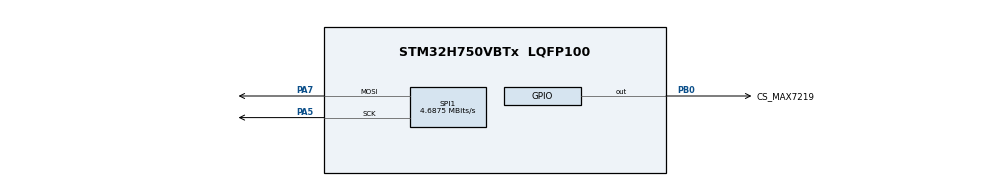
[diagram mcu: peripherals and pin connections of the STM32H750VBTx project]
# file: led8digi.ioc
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Mcu.Family=STM32H7
Mcu.Name=STM32H750VBTx
Mcu.Package=LQFP100
NVIC.PriorityGroup=NVIC_PRIORITYGROUP_4
PA5.Mode=TX_Only_Simplex_Unidirect_Master
PA5.Signal=SPI1_SCK
PA7.Mode=TX_Only_Simplex_Unidirect_Master
PA7.Signal=SPI1_MOSI
PB0.GPIO_Label=CS_MAX7219
PB0.GPIO_PuPd=GPIO_NOPULL
PB0.GPIO_Speed=GPIO_SPEED_FREQ_VERY_HIGH
PB0.Signal=GPIO_Output
PH0-OSC_IN\ (PH0).Mode=HSE-External-Oscillator
PH0-OSC_IN\ (PH0).Signal=RCC_OSC_IN
PH1-OSC_OUT\ (PH1).Mode=HSE-External-Oscillator
PH1-OSC_OUT\ (PH1).Signal=RCC_OSC_OUT
ProjectManager.HeapSize=0x200
ProjectManager.StackSize=0x400
ProjectManager.TargetToolchain=STM32CubeIDE
RCC.ADCFreq_Value=129000000
RCC.APB1Freq_Value=64000000
RCC.APB2Freq_Value=64000000
RCC.APB3Freq_Value=64000000
RCC.APB4Freq_Value=64000000
RCC.CortexFreq_Value=64000000
RCC.DIVM1=4
RCC.DIVN1=9
RCC.HCLKFreq_Value=64000000
RCC.PLL1_VCI_Range=RCC_PLL1VCIRANGE_3
RCC.PLLFRACN=3072
RCC.PREFETCH_ENABLE=1
RCC.SYSCLKFreq_VALUE=64000000
RCC.USBFreq_Value=75000000
SPI1.BaudRatePrescaler=SPI_BAUDRATEPRESCALER_16
SPI1.CalculateBaudRate=4.6875 MBits/s
SPI1.DataSize=SPI_DATASIZE_8BIT
SPI1.Direction=SPI_DIRECTION_2LINES_TXONLY
SPI1.Mode=SPI_MODE_MASTER
SPI1.VirtualType=VM_MASTER
board=custom

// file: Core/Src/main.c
/* USER CODE BEGIN Header */
/**
  ******************************************************************************
  * @file           : main.c
  * @brief          : Main program body
  ******************************************************************************
  * @attention
  *
  * Copyright (c) 2023 STMicroelectronics.
  * All rights reserved.
  *
  * This software is licensed under terms that can be found in the LICENSE file
  * in the root directory of this software component.
  * If no LICENSE file comes with this software, it is provided AS-IS.
  *
  ******************************************************************************
  */
/* USER CODE END Header */
#include "main.h"

/* USER CODE BEGIN Includes */
#include "max7219.h"
/* USER CODE END Includes */

SPI_HandleTypeDef hspi1;

void SystemClock_Config(void);
static void MX_GPIO_Init(void);
static void MX_SPI1_Init(void);

int main(void)
{

  /* MCU Configuration--------------------------------------------------------*/

  /* Reset of all peripherals, Initializes the Flash interface and the Systick. */
  HAL_Init();

  /* Configure the system clock */
  SystemClock_Config();

  /* Initialize all configured peripherals */
  MX_GPIO_Init();
  MX_SPI1_Init();
  /* USER CODE BEGIN 2 */
  max7219_Init(7);
  max7219_Decode_On();

  /* USER CODE END 2 */

  /* Infinite loop */
  while (1)
  {

    /* USER CODE BEGIN 3 */
	  max7219_Clean();
	    max7219_PrintFtos(DIGIT_8, -3.14, 2);
	    max7219_PrintDigit(DIGIT_4, LETTER_H, false);
	    max7219_PrintDigit(DIGIT_3, LETTER_E, false);
	    max7219_PrintDigit(DIGIT_2, LETTER_L, false);
	    max7219_PrintDigit(DIGIT_1, LETTER_P, false);
	    HAL_Delay(1500);
	   // max7219_Clean();
	  //  max7219_PrintNtos(DIGIT_8, 765, 4);
	   // max7219_PrintItos(DIGIT_3, 4321);
	   // HAL_Delay(1500);
  }
  /* USER CODE END 3 */
}

void SystemClock_Config(void)
{
  RCC_OscInitTypeDef RCC_OscInitStruct = {0};
  RCC_ClkInitTypeDef RCC_ClkInitStruct = {0};

  /** Supply configuration update enable
  */
  HAL_PWREx_ConfigSupply(PWR_LDO_SUPPLY);

  /** Configure the main internal regulator output voltage
  */
  __HAL_PWR_VOLTAGESCALING_CONFIG(PWR_REGULATOR_VOLTAGE_SCALE3);

  while(!__HAL_PWR_GET_FLAG(PWR_FLAG_VOSRDY)) {}

  /** Initializes the RCC Oscillators according to the specified parameters
  * in the RCC_OscInitTypeDef structure.
  */
  RCC_OscInitStruct.OscillatorType = RCC_OSCILLATORTYPE_HSI;
  RCC_OscInitStruct.HSIState = RCC_HSI_DIV1;
  RCC_OscInitStruct.HSICalibrationValue = RCC_HSICALIBRATION_DEFAULT;
  RCC_OscInitStruct.PLL.PLLState = RCC_PLL_ON;
  RCC_OscInitStruct.PLL.PLLSource = RCC_PLLSOURCE_HSI;
  RCC_OscInitStruct.PLL.PLLM = 4;
  RCC_OscInitStruct.PLL.PLLN = 9;
  RCC_OscInitStruct.PLL.PLLP = 2;
  RCC_OscInitStruct.PLL.PLLQ = 2;
  RCC_OscInitStruct.PLL.PLLR = 2;
  RCC_OscInitStruct.PLL.PLLRGE = RCC_PLL1VCIRANGE_3;
  RCC_OscInitStruct.PLL.PLLVCOSEL = RCC_PLL1VCOMEDIUM;
  RCC_OscInitStruct.PLL.PLLFRACN = 3072;
  if (HAL_RCC_OscConfig(&RCC_OscInitStruct) != HAL_OK)
  {
    Error_Handler();
  }

  /** Initializes the CPU, AHB and APB buses clocks
  */
  RCC_ClkInitStruct.ClockType = RCC_CLOCKTYPE_HCLK|RCC_CLOCKTYPE_SYSCLK
                              |RCC_CLOCKTYPE_PCLK1|RCC_CLOCKTYPE_PCLK2
                              |RCC_CLOCKTYPE_D3PCLK1|RCC_CLOCKTYPE_D1PCLK1;
  RCC_ClkInitStruct.SYSCLKSource = RCC_SYSCLKSOURCE_HSI;
  RCC_ClkInitStruct.SYSCLKDivider = RCC_SYSCLK_DIV1;
  RCC_ClkInitStruct.AHBCLKDivider = RCC_HCLK_DIV1;
  RCC_ClkInitStruct.APB3CLKDivider = RCC_APB3_DIV1;
  RCC_ClkInitStruct.APB1CLKDivider = RCC_APB1_DIV1;
  RCC_ClkInitStruct.APB2CLKDivider = RCC_APB2_DIV1;
  RCC_ClkInitStruct.APB4CLKDivider = RCC_APB4_DIV1;

  if (HAL_RCC_ClockConfig(&RCC_ClkInitStruct, FLASH_LATENCY_1) != HAL_OK)
  {
    Error_Handler();
  }
}

static void MX_SPI1_Init(void)
{

  /* SPI1 parameter configuration*/
  hspi1.Instance = SPI1;
  hspi1.Init.Mode = SPI_MODE_MASTER;
  hspi1.Init.Direction = SPI_DIRECTION_2LINES_TXONLY;
  hspi1.Init.DataSize = SPI_DATASIZE_8BIT;
  hspi1.Init.CLKPolarity = SPI_POLARITY_LOW;
  hspi1.Init.CLKPhase = SPI_PHASE_1EDGE;
  hspi1.Init.NSS = SPI_NSS_SOFT;
  hspi1.Init.BaudRatePrescaler = SPI_BAUDRATEPRESCALER_16;
  hspi1.Init.FirstBit = SPI_FIRSTBIT_MSB;
  hspi1.Init.TIMode = SPI_TIMODE_DISABLE;
  hspi1.Init.CRCCalculation = SPI_CRCCALCULATION_DISABLE;
  hspi1.Init.CRCPolynomial = 0x0;
  hspi1.Init.NSSPMode = SPI_NSS_PULSE_ENABLE;
  hspi1.Init.NSSPolarity = SPI_NSS_POLARITY_LOW;
  hspi1.Init.FifoThreshold = SPI_FIFO_THRESHOLD_01DATA;
  hspi1.Init.TxCRCInitializationPattern = SPI_CRC_INITIALIZATION_ALL_ZERO_PATTERN;
  hspi1.Init.RxCRCInitializationPattern = SPI_CRC_INITIALIZATION_ALL_ZERO_PATTERN;
  hspi1.Init.MasterSSIdleness = SPI_MASTER_SS_IDLENESS_00CYCLE;
  hspi1.Init.MasterInterDataIdleness = SPI_MASTER_INTERDATA_IDLENESS_00CYCLE;
  hspi1.Init.MasterReceiverAutoSusp = SPI_MASTER_RX_AUTOSUSP_DISABLE;
  hspi1.Init.MasterKeepIOState = SPI_MASTER_KEEP_IO_STATE_DISABLE;
  hspi1.Init.IOSwap = SPI_IO_SWAP_DISABLE;
  if (HAL_SPI_Init(&hspi1) != HAL_OK)
  {
    Error_Handler();
  }

}

static void MX_GPIO_Init(void)
{
  GPIO_InitTypeDef GPIO_InitStruct = {0};

  /* GPIO Ports Clock Enable */
  __HAL_RCC_GPIOH_CLK_ENABLE();
  __HAL_RCC_GPIOA_CLK_ENABLE();
  __HAL_RCC_GPIOB_CLK_ENABLE();

  /*Configure GPIO pin Output Level */
  HAL_GPIO_WritePin(CS_MAX7219_GPIO_Port, CS_MAX7219_Pin, GPIO_PIN_RESET);

  /*Configure GPIO pin : CS_MAX7219_Pin */
  GPIO_InitStruct.Pin = CS_MAX7219_Pin;
  GPIO_InitStruct.Mode = GPIO_MODE_OUTPUT_PP;
  GPIO_InitStruct.Pull = GPIO_NOPULL;
  GPIO_InitStruct.Speed = GPIO_SPEED_FREQ_VERY_HIGH;
  HAL_GPIO_Init(CS_MAX7219_GPIO_Port, &GPIO_InitStruct);

}

void Error_Handler(void)
{
  __disable_irq();
  while (1)
  {
  }
}
